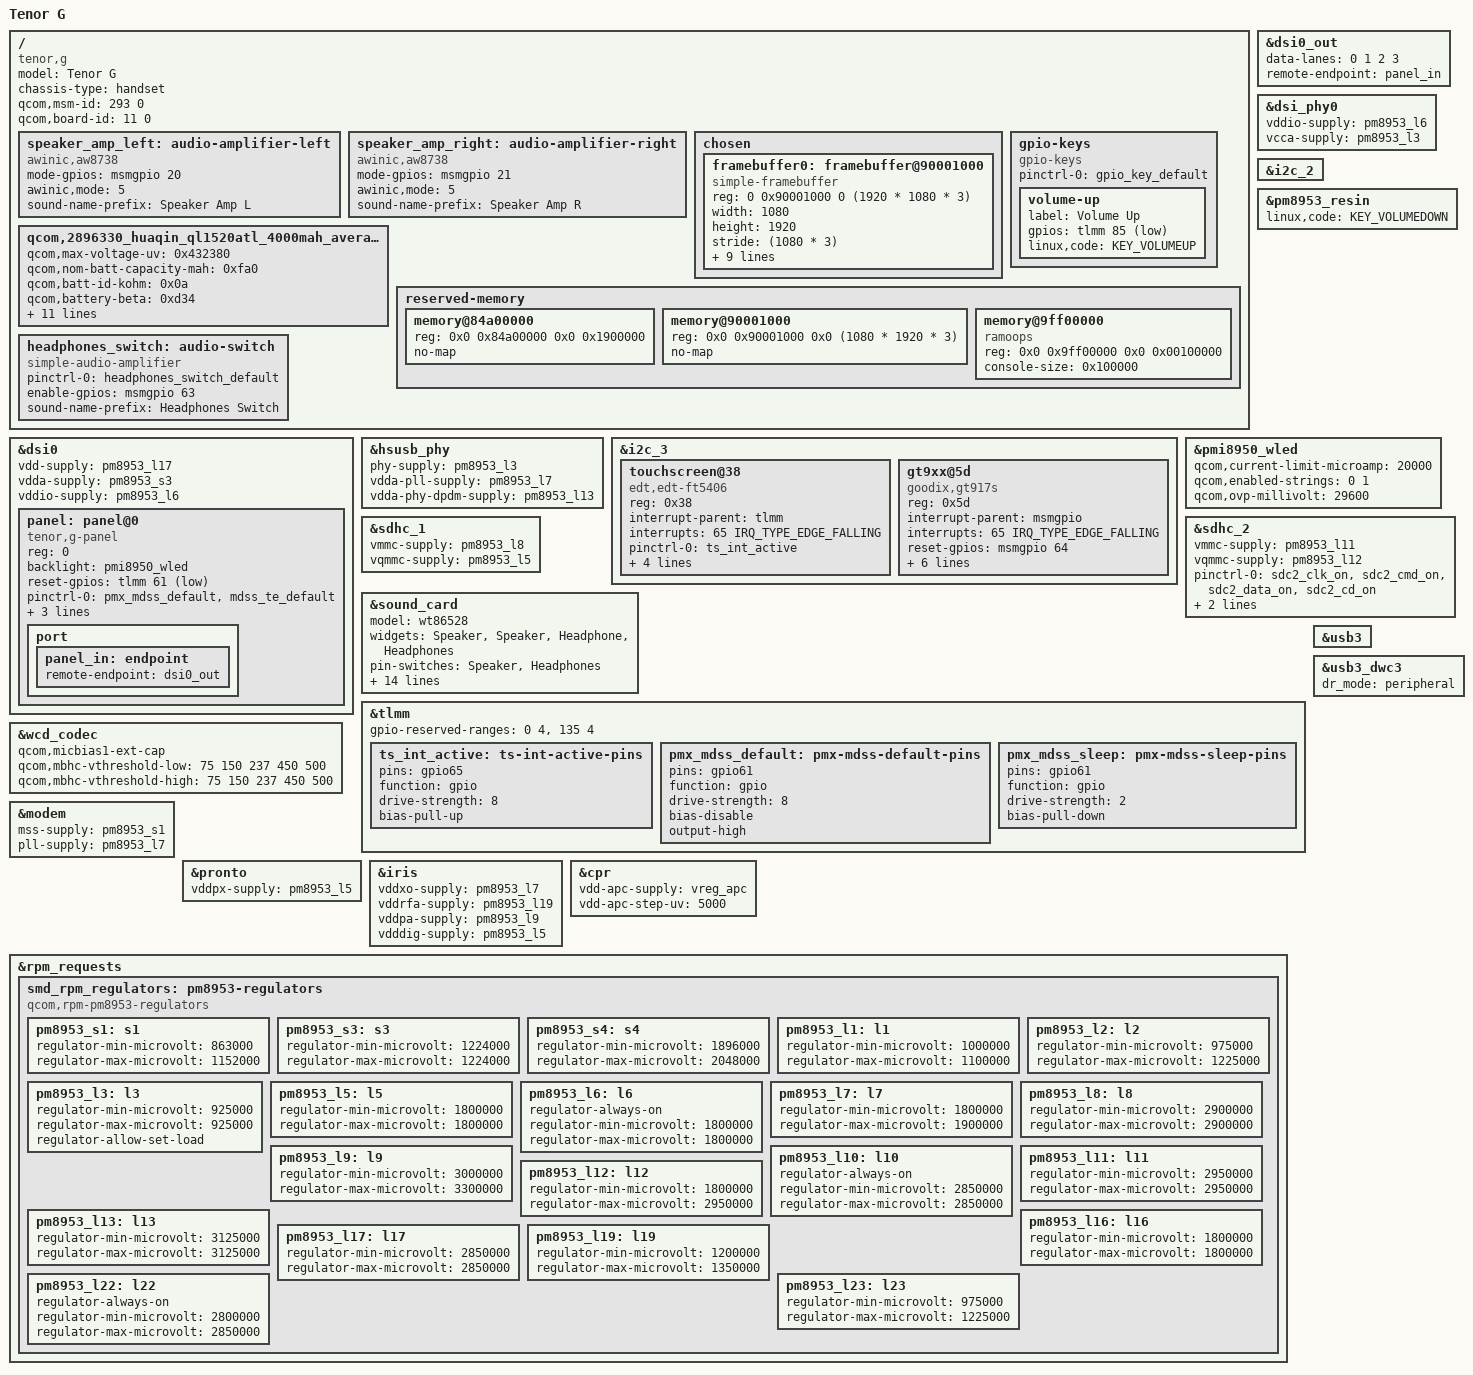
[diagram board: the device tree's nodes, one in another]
// SPDX-License-Identifier: BSD-3-Clause
// Copyright (c) 2022, The Linux Foundation. All rights reserved.
/dts-v1/;

#include "msm8953.dtsi"
#include "pm8953.dtsi"
#include "pmi8950.dtsi"
#include <dt-bindings/leds/common.h>

/ {
	model = "Tenor G";
	compatible = "tenor,g", "qcom,msm8953";
	chassis-type = "handset";
	qcom,msm-id = <293 0>;
	qcom,board-id = <11 0>;

	/* left AW8736 */
	speaker_amp_left: audio-amplifier-left {
		compatible = "awinic,aw8738";
		mode-gpios = <&msmgpio 20 GPIO_ACTIVE_HIGH>;
		awinic,mode = <5>;
		sound-name-prefix = "Speaker Amp L";
	};

	/* right AW8736 */
	speaker_amp_right: audio-amplifier-right {
		compatible = "awinic,aw8738";
		mode-gpios = <&msmgpio 21 GPIO_ACTIVE_HIGH>;
		awinic,mode = <5>;
		sound-name-prefix = "Speaker Amp R";
	};
	
	chosen {
		#address-cells = <2>;
		#size-cells = <2>;
		ranges;

		framebuffer0: framebuffer@90001000 {
			compatible = "simple-framebuffer";
			reg = <0 0x90001000 0 (1920 * 1080 * 3)>;

			width = <1080>;
			height = <1920>;
			stride = <(1080 * 3)>;
			format = "r8g8b8";

			power-domains = <&gcc MDSS_GDSC>;

			clocks = <&gcc GCC_MDSS_AHB_CLK>,
				 <&gcc GCC_MDSS_AXI_CLK>,
				 <&gcc GCC_MDSS_VSYNC_CLK>,
				 <&gcc GCC_MDSS_MDP_CLK>,
				 <&gcc GCC_MDSS_BYTE0_CLK>,
				 <&gcc GCC_MDSS_PCLK0_CLK>,
				 <&gcc GCC_MDSS_ESC0_CLK>;
		};
	};

	gpio-keys {
		compatible = "gpio-keys";

		pinctrl-names = "default";
		pinctrl-0 = <&gpio_key_default>;

		volume-up {
			label = "Volume Up";
			gpios = <&tlmm 85 GPIO_ACTIVE_LOW>;
			linux,code = <KEY_VOLUMEUP>;
		};
	};

	qcom,2896330_huaqin_ql1520atl_4000mah_averaged_masterslave_may8th2017 {
		qcom,max-voltage-uv = <0x432380>;
		qcom,nom-batt-capacity-mah = <0xfa0>;
		qcom,batt-id-kohm = <0x0a>;
		qcom,battery-beta = <0xd34>;
		qcom,battery-type = "2896330_huaqin_ql1520atl_4000mah_averaged_masterslave_may8th2017";
		qcom,fg-cc-cv-threshold-mv = <0x1126>;
		qcom,chg-rslow-comp-c1 = <0x2d8df4>;
		qcom,chg-rslow-comp-c2 = <0x36bad8>;
		qcom,chg-rs-to-rslow = <0xec40c>;
		qcom,chg-rslow-comp-thr = <0x99>;
		qcom,checksum = <0x2df5>;
		qcom,gui-version = "PMI8950GUI - 2.0.0.16";
		qcom,fg-profile-data = <0xda83947c 0xf9803677 0x63836974 0x75897194 0x22827599
		0x14bc21c8 0x57110488 0xc47dcd81 0x5a7c5383 0x87691c7a 0x26873382 0x409a95bd 
		0xd2ca590e 0x7c0f9d5a 0x1470eefc 0xe9267445 0xde330000 0xd9469b39 0xfe120000 
		0x00 0x00 0x9705f6a 0x10490489 0xae75716a 0x805c5b7b 0xc26fa863 0x156c57a1 
		0x230c6106 0x5ea0710c 0x2800ff36 0xf0113003 0x0c>;
		};
	
	reserved-memory {
		/delete-node/memory@85b00000;

		memory@84a00000 {
			reg = <0x0 0x84a00000 0x0 0x1900000>;
			no-map;
		};

		memory@90001000 {
			reg = <0x0 0x90001000 0x0 (1080 * 1920 * 3)>;
			no-map;
		};

		memory@9ff00000 {
			compatible = "ramoops";
			reg = <0x0 0x9ff00000 0x0 0x00100000>;
			console-size = <0x100000>;
		};
	};
	
	headphones_switch: audio-switch {
		compatible = "simple-audio-amplifier";

		pinctrl-names = "default";
		pinctrl-0 = <&headphones_switch_default>;

		enable-gpios = <&msmgpio 63 GPIO_ACTIVE_HIGH>;
		sound-name-prefix = "Headphones Switch";
	};
};
&dsi0 {
	vdd-supply = <&pm8953_l17>;
	vdda-supply = <&pm8953_s3>;
	vddio-supply = <&pm8953_l6>;
        
	panel: panel@0 {
		compatible = "tenor,g-panel";
		reg = <0>;

		backlight = <&pmi8950_wled>;

		reset-gpios = <&tlmm 61 GPIO_ACTIVE_LOW>;

		pinctrl-names = "default", "sleep";
		pinctrl-0 = <&pmx_mdss_default &mdss_te_default>;
		pinctrl-1 = <&pmx_mdss_sleep &mdss_te_default>;

		vsp-supply = <&lab_vreg>;
		vsn-supply = <&ibb_vreg>;

		port {
			panel_in: endpoint {
				remote-endpoint = <&dsi0_out>;
			};
		};
	};
};

&dsi0_out {
	data-lanes = <0 1 2 3>;
	remote-endpoint = <&panel_in>;
};

&dsi_phy0 {
        vddio-supply = <&pm8953_l6>;
        vcca-supply = <&pm8953_l3>;
};

&hsusb_phy {
	status = "okay";
	
	phy-supply = <&pm8953_l3>;
	vdda-pll-supply = <&pm8953_l7>;
	vdda-phy-dpdm-supply = <&pm8953_l13>;
};

&i2c_2 {
	status = "okay";

	
};

&i2c_3 {
	status = "okay";

	touchscreen@38 {
		compatible = "edt,edt-ft5406", "edt,edt-ft5x06";
		reg = <0x38>;

		interrupt-parent = <&tlmm>;
		interrupts = <65 IRQ_TYPE_EDGE_FALLING>;

		pinctrl-names = "default";
		pinctrl-0 = <&ts_int_active>;

		reset-gpios = <&tlmm 64 GPIO_ACTIVE_LOW>;

		vcc-supply = <&pm8953_l10>;

		touchscreen-size-x = <1080>;
		touchscreen-size-y = <1920>;
	};
	
	gt9xx@5d {
		compatible = "goodix,gt917s";
		reg = <0x5d>;

		interrupt-parent = <&msmgpio>;
		interrupts = <65 IRQ_TYPE_EDGE_FALLING>;

		reset-gpios = <&msmgpio 64 0x0>;
		irq-gpios = <&msmgpio 65 0x2008>;
		irq-flags = <1>;

		AVDD28-supply = <&pm8953_l10>;
		VDDIO-supply = <&pm8953_l6>;

		touchscreen-size-x = <1080>;
		touchscreen-size-y = <1920>;
	};
};

&pm8953_resin {
	status = "okay";
	linux,code = <KEY_VOLUMEDOWN>;
};

&pmi8950_wled {
	status = "okay";

	/* Don't copy-paste! See pmi8950.dtsi */

	qcom,current-limit-microamp = <20000>;
	qcom,enabled-strings = <0 1>;
	qcom,ovp-millivolt = <29600>;
};

&sdhc_1 {
	status = "okay";
	
	vmmc-supply = <&pm8953_l8>;
	vqmmc-supply = <&pm8953_l5>;
};

&sdhc_2 {
	status = "okay";
	
	vmmc-supply = <&pm8953_l11>;
	vqmmc-supply = <&pm8953_l12>;
	pinctrl-names = "default", "sleep";
	pinctrl-0 = <&sdc2_clk_on &sdc2_cmd_on &sdc2_data_on &sdc2_cd_on>;
	pinctrl-1 = <&sdc2_clk_off &sdc2_cmd_off &sdc2_data_off &sdc2_cd_off>;

	// cd-gpios = <&tlmm 133 GPIO_ACTIVE_LOW>;
};

&sound_card {
	status = "okay";

	model = "wt86528";
	widgets =
		"Speaker", "Speaker",
		"Headphone", "Headphones";
	pin-switches = "Speaker", "Headphones";

	pinctrl-names = "default", "sleep";
	pinctrl-0 = <&cdc_pdm_lines_act &cdc_pdm_lines_2_act &cdc_pdm_comp_lines_act>;
	pinctrl-1 = <&cdc_pdm_lines_sus &cdc_pdm_lines_2_sus &cdc_pdm_comp_lines_act>;

	/delete-property/ audio-routing;
	audio-routing =
		"Speaker", "Speaker Amp L OUT",
		"Speaker", "Speaker Amp R OUT",
		"Speaker Amp L IN", "HPH_L",
		"Speaker Amp R IN", "HPH_R",
		"AMIC1", "MIC BIAS External1",
		"AMIC2", "MIC BIAS Internal2",
		"AMIC3", "MIC BIAS External1",
		"MM_DL1", "MultiMedia1 Playback",
		"MM_DL3", "MultiMedia3 Playback",
		"MM_DL4", "MultiMedia4 Playback",
		"MultiMedia2 Capture", "MM_UL2";
};

&tlmm {
	gpio-reserved-ranges = <0 4>, <135 4>;

	ts_int_active: ts-int-active-pins {
		pins = "gpio65";
		function = "gpio";
		drive-strength = <8>;
		bias-pull-up;
	};
	
	pmx_mdss_default: pmx-mdss-default-pins {
		pins = "gpio61";
		function = "gpio";
		drive-strength = <8>;
		bias-disable;
		output-high;
	};

	pmx_mdss_sleep: pmx-mdss-sleep-pins {
		pins = "gpio61";
		function = "gpio";
		drive-strength = <2>;
		bias-pull-down;
	};
};

&usb3 {
	status = "okay";
};

&usb3_dwc3 {
	dr_mode = "peripheral";
};

&wcd_codec {
	qcom,micbias1-ext-cap;
	qcom,mbhc-vthreshold-low = <75 150 237 450 500>;
	qcom,mbhc-vthreshold-high = <75 150 237 450 500>;
};

&hsusb_phy {
	phy-supply = <&pm8953_l3>;
	vdda-pll-supply = <&pm8953_l7>;
	vdda-phy-dpdm-supply = <&pm8953_l13>;
};

&sdhc_1 {
	vmmc-supply = <&pm8953_l8>;
	vqmmc-supply = <&pm8953_l5>;
};

&sdhc_2 {
	vmmc-supply = <&pm8953_l11>;
	vqmmc-supply = <&pm8953_l12>;
};

&modem {
	mss-supply = <&pm8953_s1>;
	pll-supply = <&pm8953_l7>;
};

&pronto {
	vddpx-supply = <&pm8953_l5>;
};

&iris {
	vddxo-supply = <&pm8953_l7>;
	vddrfa-supply = <&pm8953_l19>;
	vddpa-supply = <&pm8953_l9>;
	vdddig-supply = <&pm8953_l5>;
};

&cpr {
	vdd-apc-supply = <&vreg_apc>;
	vdd-apc-step-uv = <5000>;
};

&rpm_requests {
	smd_rpm_regulators: pm8953-regulators {
		compatible = "qcom,rpm-pm8953-regulators";

	pm8953_s1: s1 {
		regulator-min-microvolt = <863000>;
		regulator-max-microvolt = <1152000>;
	};

	pm8953_s3: s3 {
		regulator-min-microvolt = <1224000>;
		regulator-max-microvolt = <1224000>;
	};

	pm8953_s4: s4 {
		regulator-min-microvolt = <1896000>;
		regulator-max-microvolt = <2048000>;
	};

	pm8953_l1: l1 {
		regulator-min-microvolt = <1000000>;
		regulator-max-microvolt = <1100000>;
	};

	pm8953_l2: l2 {
		regulator-min-microvolt = <975000>;
		regulator-max-microvolt = <1225000>;
	};

	pm8953_l3: l3 {
		regulator-min-microvolt = <925000>;
		regulator-max-microvolt = <925000>;
		regulator-allow-set-load;
	};

	pm8953_l5: l5 {
		regulator-min-microvolt = <1800000>;
		regulator-max-microvolt = <1800000>;
	};

	pm8953_l6: l6 {
		regulator-always-on;
		regulator-min-microvolt = <1800000>;
		regulator-max-microvolt = <1800000>;
	};

	pm8953_l7: l7 {
		regulator-min-microvolt = <1800000>;
		regulator-max-microvolt = <1900000>;
	};

	pm8953_l8: l8 {
		regulator-min-microvolt = <2900000>;
		regulator-max-microvolt = <2900000>;
	};

	pm8953_l9: l9 {
		regulator-min-microvolt = <3000000>;
		regulator-max-microvolt = <3300000>;
	};

	pm8953_l10: l10 {
		regulator-always-on;
		regulator-min-microvolt = <2850000>;
		regulator-max-microvolt = <2850000>;
	};

	pm8953_l11: l11 {
		regulator-min-microvolt = <2950000>;
		regulator-max-microvolt = <2950000>;
	};

	pm8953_l12: l12 {
		regulator-min-microvolt = <1800000>;
		regulator-max-microvolt = <2950000>;
	};

	pm8953_l13: l13 {
		regulator-min-microvolt = <3125000>;
		regulator-max-microvolt = <3125000>;
	};

	pm8953_l16: l16 {
		regulator-min-microvolt = <1800000>;
		regulator-max-microvolt = <1800000>;
	};

	pm8953_l17: l17 {
		regulator-min-microvolt = <2850000>;
		regulator-max-microvolt = <2850000>;
	};

	pm8953_l19: l19 {
		regulator-min-microvolt = <1200000>;
		regulator-max-microvolt = <1350000>;
	};

	pm8953_l22: l22 {
		regulator-always-on;
		regulator-min-microvolt = <2800000>;
		regulator-max-microvolt = <2850000>;
	};

	pm8953_l23: l23 {
		regulator-min-microvolt = <975000>;
		regulator-max-microvolt = <1225000>;
	};
	};
};
